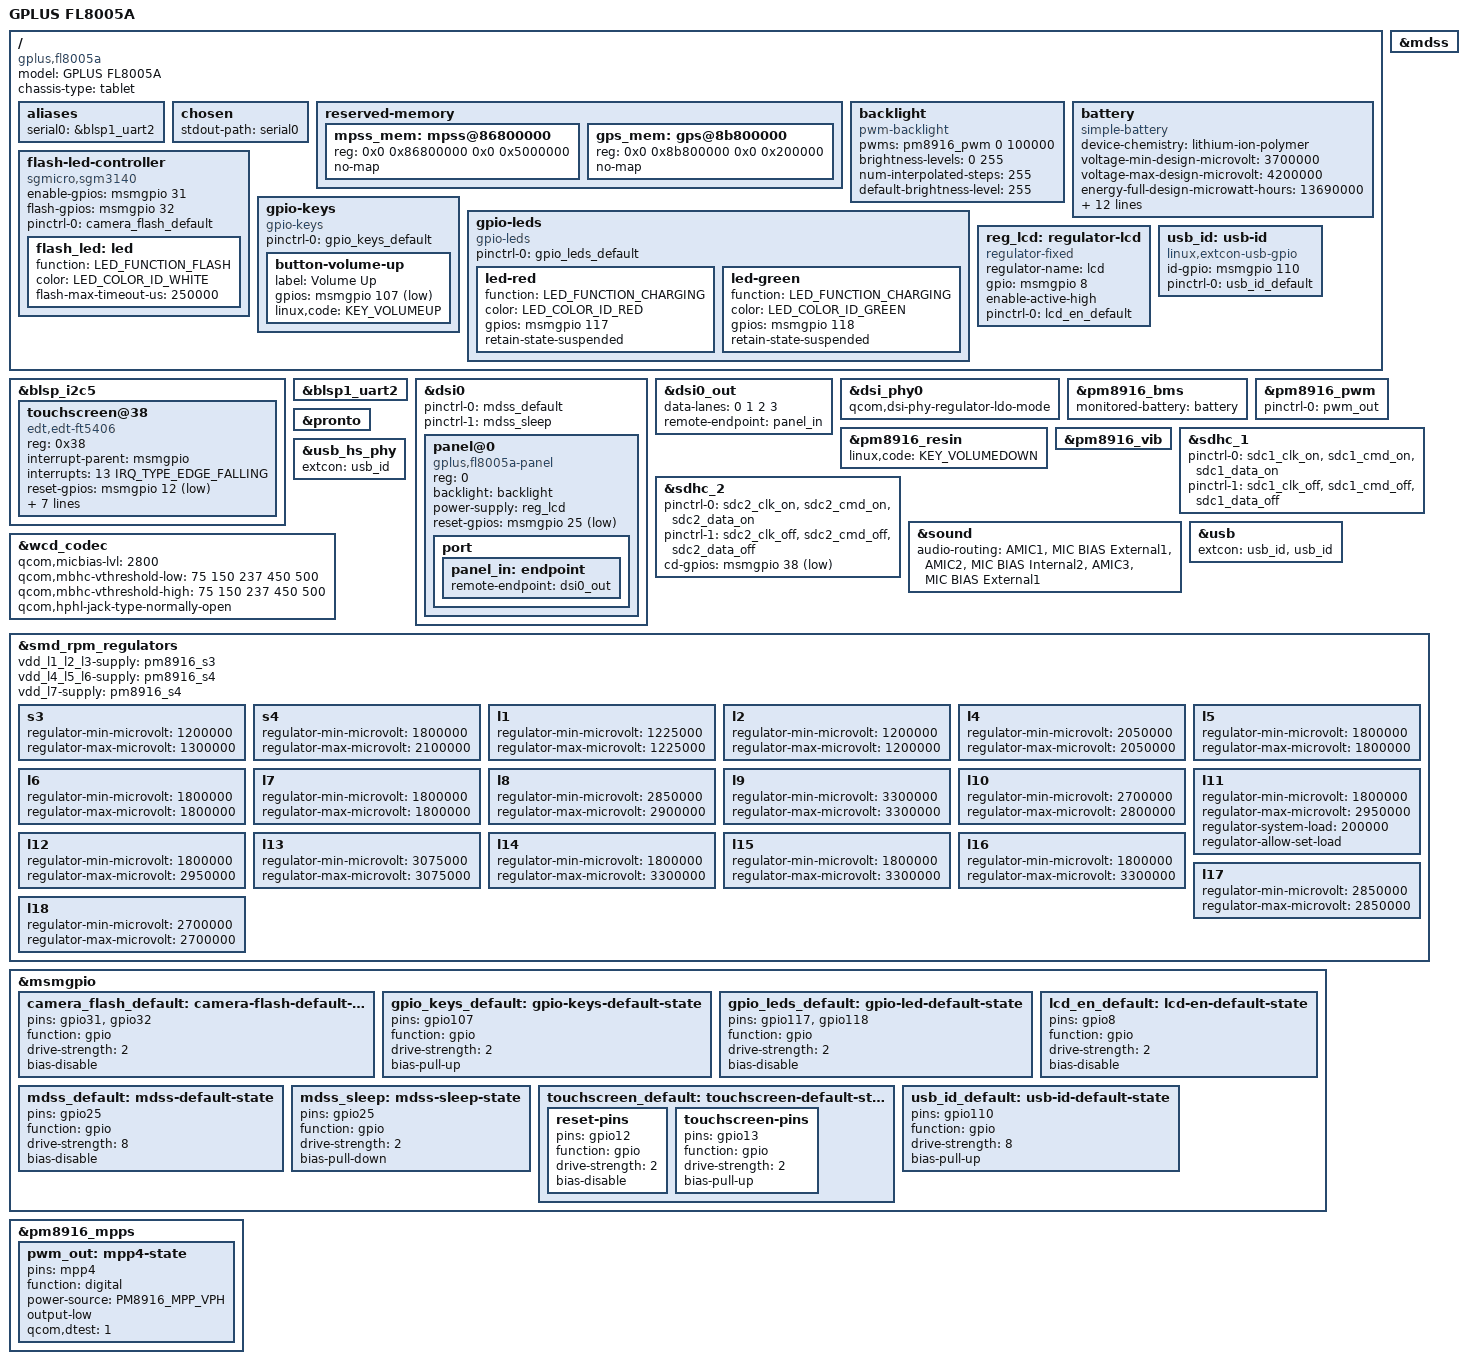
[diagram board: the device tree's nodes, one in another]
// SPDX-License-Identifier: GPL-2.0-only

/dts-v1/;

#include "msm8916-pm8916.dtsi"
#include "msm8916-modem.dtsi"

#include <dt-bindings/gpio/gpio.h>
#include <dt-bindings/input/input.h>
#include <dt-bindings/leds/common.h>
#include <dt-bindings/pinctrl/qcom,pmic-mpp.h>

/ {
	model = "GPLUS FL8005A";
	compatible = "gplus,fl8005a", "qcom,msm8916";
	chassis-type = "tablet";

	aliases {
		serial0 = &blsp1_uart2;
	};

	chosen {
		stdout-path = "serial0";
	};

	reserved-memory {
		mpss_mem: mpss@86800000 {
			reg = <0x0 0x86800000 0x0 0x5000000>;
			no-map;
		};

		gps_mem: gps@8b800000 {
			reg = <0x0 0x8b800000 0x0 0x200000>;
			no-map;
		};
	};

	backlight: backlight {
		compatible = "pwm-backlight";
		pwms = <&pm8916_pwm 0 100000>;

		brightness-levels = <0 255>;
		num-interpolated-steps = <255>;
		default-brightness-level = <255>;
	};

	battery: battery {
		compatible = "simple-battery";
		device-chemistry = "lithium-ion-polymer";
		voltage-min-design-microvolt = <3700000>;
		voltage-max-design-microvolt = <4200000>;
		energy-full-design-microwatt-hours = <13690000>;
		charge-full-design-microamp-hours = <3700000>;

		ocv-capacity-celsius = <25>;
		ocv-capacity-table-0 =
			<4186000 100>, <4126000 95>, <4078000 90>,
			<4036000 85>, <3997000 80>, <3962000 75>,
			<3932000 70>, <3904000 65>, <3874000 60>,
			<3839000 55>, <3809000 50>, <3792000 45>,
			<3780000 40>, <3772000 35>, <3764000 30>,
			<3752000 25>, <3731000 20>, <3704000 16>,
			<3677000 13>, <3670000 11>, <3668000 10>,
			<3666000 9>, <3662000 8>, <3658000 7>, <3648000 6>,
			<3624000 5>, <3580000 4>, <3518000 3>, <3434000 2>,
			<3310000 1>, <3000000 0>;
	};

	flash-led-controller {
		/* Actually qcom,leds-gpio-flash */
		compatible = "sgmicro,sgm3140";
		enable-gpios = <&msmgpio 31 GPIO_ACTIVE_HIGH>;
		flash-gpios = <&msmgpio 32 GPIO_ACTIVE_HIGH>;

		pinctrl-0 = <&camera_flash_default>;
		pinctrl-names = "default";

		flash_led: led {
			function = LED_FUNCTION_FLASH;
			color = <LED_COLOR_ID_WHITE>;
			flash-max-timeout-us = <250000>;
		};
	};

	gpio-keys {
		compatible = "gpio-keys";

		pinctrl-0 = <&gpio_keys_default>;
		pinctrl-names = "default";

		button-volume-up {
			label = "Volume Up";
			gpios = <&msmgpio 107 GPIO_ACTIVE_LOW>;
			linux,code = <KEY_VOLUMEUP>;
		};
	};

	gpio-leds {
		compatible = "gpio-leds";

		pinctrl-0 = <&gpio_leds_default>;
		pinctrl-names = "default";

		led-red {
			function = LED_FUNCTION_CHARGING;
			color = <LED_COLOR_ID_RED>;
			gpios = <&msmgpio 117 GPIO_ACTIVE_HIGH>;
			retain-state-suspended;
		};

		led-green {
			function = LED_FUNCTION_CHARGING;
			color = <LED_COLOR_ID_GREEN>;
			gpios = <&msmgpio 118 GPIO_ACTIVE_HIGH>;
			retain-state-suspended;
		};
	};

	reg_lcd: regulator-lcd {
		compatible = "regulator-fixed";
		regulator-name = "lcd";

		gpio = <&msmgpio 8 GPIO_ACTIVE_HIGH>;
		enable-active-high;

		pinctrl-0 = <&lcd_en_default>;
		pinctrl-names = "default";
	};

	usb_id: usb-id {
		compatible = "linux,extcon-usb-gpio";
		id-gpio = <&msmgpio 110 GPIO_ACTIVE_HIGH>;
		pinctrl-0 = <&usb_id_default>;
		pinctrl-names = "default";
	};
};

&blsp_i2c5 {
	status = "okay";

	touchscreen@38 {
		/* Actually ft5402 */
		compatible = "edt,edt-ft5406";
		reg = <0x38>;

		interrupt-parent = <&msmgpio>;
		interrupts = <13 IRQ_TYPE_EDGE_FALLING>;

		reset-gpios = <&msmgpio 12 GPIO_ACTIVE_LOW>;

		vcc-supply = <&pm8916_l17>;
		iovcc-supply = <&pm8916_l6>;

		touchscreen-size-x = <800>;
		touchscreen-size-y = <500>;
		touchscreen-inverted-x;
		touchscreen-swapped-x-y;

		pinctrl-0 = <&touchscreen_default>;
		pinctrl-names = "default";
	};
};

&blsp1_uart2 {
	status = "okay";
};

&dsi0 {
	pinctrl-0 = <&mdss_default>;
	pinctrl-1 = <&mdss_sleep>;
	pinctrl-names = "default", "sleep";

	panel@0 {
		compatible = "gplus,fl8005a-panel";
		reg = <0>;

		backlight = <&backlight>;
		power-supply = <&reg_lcd>;

		reset-gpios = <&msmgpio 25 GPIO_ACTIVE_LOW>;

		port {
			panel_in: endpoint {
				remote-endpoint = <&dsi0_out>;
			};
		};
	};
};

&dsi0_out {
	data-lanes = <0 1 2 3>;
	remote-endpoint = <&panel_in>;
};

&dsi_phy0 {
	qcom,dsi-phy-regulator-ldo-mode;
};

&mdss {
	status = "okay";
};

&pm8916_bms {
	monitored-battery = <&battery>;
	status = "okay";
};

&pm8916_pwm {
	pinctrl-0 = <&pwm_out>;
	pinctrl-names = "default";
	status = "okay";
};

&pm8916_resin {
	linux,code = <KEY_VOLUMEDOWN>;
	status = "okay";
};

&pm8916_vib {
	status = "okay";
};

&pronto {
	status = "okay";
};

&sdhc_1 {
	pinctrl-0 = <&sdc1_clk_on &sdc1_cmd_on &sdc1_data_on>;
	pinctrl-1 = <&sdc1_clk_off &sdc1_cmd_off &sdc1_data_off>;
	pinctrl-names = "default", "sleep";

	status = "okay";
};

&sdhc_2 {
	pinctrl-0 = <&sdc2_clk_on &sdc2_cmd_on &sdc2_data_on>;
	pinctrl-1 = <&sdc2_clk_off &sdc2_cmd_off &sdc2_data_off>;
	pinctrl-names = "default", "sleep";

	cd-gpios = <&msmgpio 38 GPIO_ACTIVE_LOW>;

	status = "okay";
};

&sound {
	audio-routing =
		"AMIC1", "MIC BIAS External1",
		"AMIC2", "MIC BIAS Internal2",
		"AMIC3", "MIC BIAS External1";
	status = "okay";
};

&usb {
	extcon = <&usb_id>, <&usb_id>;
	status = "okay";
};

&usb_hs_phy {
	extcon = <&usb_id>;
};

&wcd_codec {
	qcom,micbias-lvl = <2800>;
	qcom,mbhc-vthreshold-low = <75 150 237 450 500>;
	qcom,mbhc-vthreshold-high = <75 150 237 450 500>;
	qcom,hphl-jack-type-normally-open;
};

&smd_rpm_regulators {
	vdd_l1_l2_l3-supply = <&pm8916_s3>;
	vdd_l4_l5_l6-supply = <&pm8916_s4>;
	vdd_l7-supply = <&pm8916_s4>;

	s3 {
		regulator-min-microvolt = <1200000>;
		regulator-max-microvolt = <1300000>;
	};

	s4 {
		regulator-min-microvolt = <1800000>;
		regulator-max-microvolt = <2100000>;
	};

	l1 {
		regulator-min-microvolt = <1225000>;
		regulator-max-microvolt = <1225000>;
	};

	l2 {
		regulator-min-microvolt = <1200000>;
		regulator-max-microvolt = <1200000>;
	};

	l4 {
		regulator-min-microvolt = <2050000>;
		regulator-max-microvolt = <2050000>;
	};

	l5 {
		regulator-min-microvolt = <1800000>;
		regulator-max-microvolt = <1800000>;
	};

	l6 {
		regulator-min-microvolt = <1800000>;
		regulator-max-microvolt = <1800000>;
	};

	l7 {
		regulator-min-microvolt = <1800000>;
		regulator-max-microvolt = <1800000>;
	};

	l8 {
		regulator-min-microvolt = <2850000>;
		regulator-max-microvolt = <2900000>;
	};

	l9 {
		regulator-min-microvolt = <3300000>;
		regulator-max-microvolt = <3300000>;
	};

	l10 {
		regulator-min-microvolt = <2700000>;
		regulator-max-microvolt = <2800000>;
	};

	l11 {
		regulator-min-microvolt = <1800000>;
		regulator-max-microvolt = <2950000>;
		regulator-system-load = <200000>;
		regulator-allow-set-load;
	};

	l12 {
		regulator-min-microvolt = <1800000>;
		regulator-max-microvolt = <2950000>;
	};

	l13 {
		regulator-min-microvolt = <3075000>;
		regulator-max-microvolt = <3075000>;
	};

	l14 {
		regulator-min-microvolt = <1800000>;
		regulator-max-microvolt = <3300000>;
	};

	l15 {
		regulator-min-microvolt = <1800000>;
		regulator-max-microvolt = <3300000>;
	};

	l16 {
		regulator-min-microvolt = <1800000>;
		regulator-max-microvolt = <3300000>;
	};

	l17 {
		regulator-min-microvolt = <2850000>;
		regulator-max-microvolt = <2850000>;
	};

	l18 {
		regulator-min-microvolt = <2700000>;
		regulator-max-microvolt = <2700000>;
	};
};

&msmgpio {
	camera_flash_default: camera-flash-default-state {
		pins = "gpio31", "gpio32";
		function = "gpio";
		drive-strength = <2>;
		bias-disable;
	};

	gpio_keys_default: gpio-keys-default-state {
		pins = "gpio107";
		function = "gpio";
		drive-strength = <2>;
		bias-pull-up;
	};

	gpio_leds_default: gpio-led-default-state {
		pins = "gpio117", "gpio118";
		function = "gpio";
		drive-strength = <2>;
		bias-disable;
	};

	lcd_en_default: lcd-en-default-state {
		pins = "gpio8";
		function = "gpio";
		drive-strength = <2>;
		bias-disable;
	};

	mdss_default: mdss-default-state {
		pins = "gpio25";
		function = "gpio";
		drive-strength = <8>;
		bias-disable;
	};

	mdss_sleep: mdss-sleep-state {
		pins = "gpio25";
		function = "gpio";
		drive-strength = <2>;
		bias-pull-down;
	};

	touchscreen_default: touchscreen-default-state {
		reset-pins {
			pins = "gpio12";
			function = "gpio";
			drive-strength = <2>;
			bias-disable;
		};

		touchscreen-pins {
			pins = "gpio13";
			function = "gpio";
			drive-strength = <2>;
			bias-pull-up;
		};
	};

	usb_id_default: usb-id-default-state {
		pins = "gpio110";
		function = "gpio";
		drive-strength = <8>;
		bias-pull-up;
	};
};

&pm8916_mpps {
	pwm_out: mpp4-state {
		pins = "mpp4";
		function = "digital";
		power-source = <PM8916_MPP_VPH>;
		output-low;
		qcom,dtest = <1>;
	};
};
